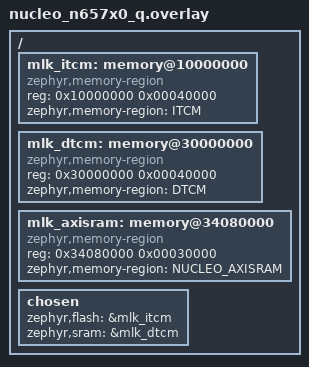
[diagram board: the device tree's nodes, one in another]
/*
 * Copyright (c) The mlkem-native project authors
 * SPDX-License-Identifier: Apache-2.0 OR ISC OR MIT
 */

/ {
    mlk_itcm: memory@10000000 {
        compatible = "zephyr,memory-region", "arm,itcm";
        reg = <0x10000000 0x00040000>;
        zephyr,memory-region = "ITCM";
    };

    mlk_dtcm: memory@30000000 {
        compatible = "zephyr,memory-region", "arm,dtcm";
        reg = <0x30000000 0x00040000>;
        zephyr,memory-region = "DTCM";
    };

    mlk_axisram: memory@34080000 {
        compatible = "zephyr,memory-region", "mmio-sram";
        reg = <0x34080000 0x00030000>;
        zephyr,memory-region = "NUCLEO_AXISRAM";
    };

    chosen {
        zephyr,flash = &mlk_itcm;
        zephyr,sram = &mlk_dtcm;
    };
};
